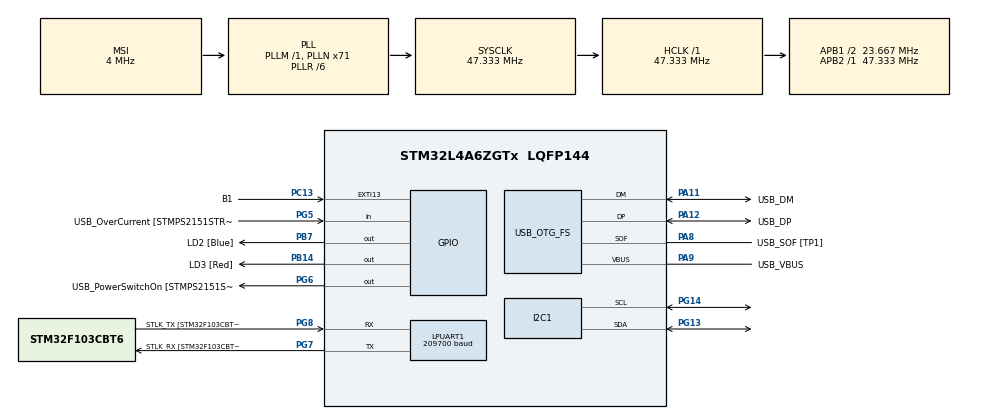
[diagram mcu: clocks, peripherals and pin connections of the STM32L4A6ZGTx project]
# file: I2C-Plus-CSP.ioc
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FREERTOS.Tasks01=defaultTask,24,128,StartDefaultTask,Default,NULL,Dynamic,NULL,NULL;I2C1MasterTask,40,128,vI2CMasterTask,As external,&hi2c1,Dynamic,NULL,NULL
FREERTOS.configUSE_NEWLIB_REENTRANT=1
I2C1.Timing=0x00505B89
LPUART1.AutoBaudRateEnableParam=UART_ADVFEATURE_AUTOBAUDRATE_DISABLE
LPUART1.BaudRate=209700
LPUART1.DMADisableonRxErrorParam=UART_ADVFEATURE_DMA_ENABLEONRXERROR
LPUART1.DataInvertParam=UART_ADVFEATURE_DATAINV_DISABLE
LPUART1.MSBFirstParam=UART_ADVFEATURE_MSBFIRST_DISABLE
LPUART1.Mode=UART_MODE_TX_RX
LPUART1.OneBitSampling=UART_ONE_BIT_SAMPLE_DISABLE
LPUART1.OverrunDisableParam=UART_ADVFEATURE_OVERRUN_ENABLE
LPUART1.Parity=UART_PARITY_NONE
LPUART1.RxPinLevelInvertParam=UART_ADVFEATURE_RXINV_DISABLE
LPUART1.StopBits=UART_STOPBITS_1
LPUART1.SwapParam=UART_ADVFEATURE_SWAP_DISABLE
LPUART1.TxPinLevelInvertParam=UART_ADVFEATURE_TXINV_DISABLE
LPUART1.WordLength=UART_WORDLENGTH_7B
Mcu.Family=STM32L4
Mcu.Name=STM32L4A6ZGTx
Mcu.Package=LQFP144
NVIC.PriorityGroup=NVIC_PRIORITYGROUP_4
NVIC.TIM1_UP_TIM16_IRQn=true\:15\:0\:false\:false\:true\:false\:false\:true\:true
NVIC.TimeBase=TIM1_UP_TIM16_IRQn
NVIC.TimeBaseIP=TIM1
PA10.GPIO_Label=USB_ID
PA10.Signal=USB_OTG_FS_ID
PA11.GPIO_Label=USB_DM
PA11.Mode=Device_Only
PA11.Signal=USB_OTG_FS_DM
PA12.GPIO_Label=USB_DP
PA12.Mode=Device_Only
PA12.Signal=USB_OTG_FS_DP
PA13\ (JTMS/SWDIO).GPIO_Label=TMS
PA13\ (JTMS/SWDIO).Mode=Trace_Asynchronous_SW
PA13\ (JTMS/SWDIO).Signal=SYS_JTMS-SWDIO
PA14\ (JTCK/SWCLK).GPIO_Label=TCK
PA14\ (JTCK/SWCLK).Mode=Trace_Asynchronous_SW
PA14\ (JTCK/SWCLK).Signal=SYS_JTCK-SWCLK
PA8.GPIO_Label=USB_SOF [TP1]
PA8.Mode=Activate_SOF_FS
PA8.Signal=USB_OTG_FS_SOF
PA9.GPIO_Label=USB_VBUS
PA9.Mode=Activate_VBUS
PA9.Signal=USB_OTG_FS_VBUS
PB14.GPIO_Label=LD3 [Red]
PB14.Signal=GPIO_Output
PB3\ (JTDO/TRACESWO).GPIO_Label=SWO
PB3\ (JTDO/TRACESWO).Mode=Trace_Asynchronous_SW
PB3\ (JTDO/TRACESWO).Signal=SYS_JTDO-SWO
PB7.GPIO_Label=LD2 [Blue]
PB7.Signal=GPIO_Output
PC13.GPIO_Label=B1
PC13.Signal=GPXTI13
PC14-OSC32_IN\ (PC14).Mode=LSE-External-Oscillator
PC14-OSC32_IN\ (PC14).Signal=RCC_OSC32_IN
PC15-OSC32_OUT\ (PC15).Mode=LSE-External-Oscillator
PC15-OSC32_OUT\ (PC15).Signal=RCC_OSC32_OUT
PG13.Mode=I2C
PG13.Signal=I2C1_SDA
PG14.Mode=I2C
PG14.Signal=I2C1_SCL
PG5.GPIO_Label=USB_OverCurrent [STMPS2151STR_FAULT]
PG5.Signal=GPIO_Input
PG6.GPIO_Label=USB_PowerSwitchOn [STMPS2151STR_EN]
PG6.Signal=GPIO_Output
PG7.GPIO_Label=STLK_RX [STM32F103CBT6_PA3]
PG7.Mode=Asynchronous
PG7.Signal=LPUART1_TX
PG8.GPIO_Label=STLK_TX [STM32F103CBT6_PA2]
PG8.Mode=Asynchronous
PG8.Signal=LPUART1_RX
PH1-OSC_OUT\ (PH1).Signal=RCC_OSC_OUT
ProjectManager.HeapSize=0x200
ProjectManager.StackSize=0x400
ProjectManager.TargetToolchain=STM32CubeIDE
RCC.ADCFreq_Value=48000000
RCC.AHBFreq_Value=47333333.333333336
RCC.APB1CLKDivider=RCC_HCLK_DIV2
RCC.APB1Freq_Value=23666666.666666668
RCC.APB1TimFreq_Value=47333333.333333336
RCC.APB2Freq_Value=47333333.333333336
RCC.APB2TimFreq_Value=47333333.333333336
RCC.CortexFreq_Value=47333333.333333336
RCC.FLatency=FLASH_LATENCY_2
RCC.HCLKFreq_Value=47333333.333333336
RCC.HSE_VALUE=8000000
RCC.HSI48_VALUE=48000000
RCC.HSI_VALUE=16000000
RCC.MSI_VALUE=4000000
RCC.PLLN=71
RCC.PLLR=RCC_PLLR_DIV6
RCC.PLLSAI1N=24
RCC.SYSCLKFreq_VALUE=47333333.333333336
RCC.SYSCLKSource=RCC_SYSCLKSOURCE_PLLCLK
RCC.USBFreq_Value=48000000
RCC.VCOOutputFreq_Value=284000000
USB_OTG_FS.Sof_enable=ENABLE
USB_OTG_FS.VirtualMode=Device_Only
USB_OTG_FS.battery_charging_enable=ENABLE
USB_OTG_FS.low_power_enable=DISABLE
USB_OTG_FS.lpm_enable=DISABLE
USB_OTG_FS.use_dedicated_ep1=DISABLE
USB_OTG_FS.vbus_sensing_enable=ENABLE
VP_FREERTOS_VS_CMSIS_V2.Mode=CMSIS_V2
VP_SYS_VS_tim1.Mode=TIM1
board=NUCLEO-L4A6ZG

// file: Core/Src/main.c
/* USER CODE BEGIN Header */
/**
  ******************************************************************************
  * @file           : main.c
  * @brief          : Main program body
  ******************************************************************************
  * @attention
  *
  * Copyright (c) 2023 STMicroelectronics.
  * All rights reserved.
  *
  * This software is licensed under terms that can be found in the LICENSE file
  * in the root directory of this software component.
  * If no LICENSE file comes with this software, it is provided AS-IS.
  *
  ******************************************************************************
  */
/* USER CODE END Header */
#include "main.h"
#include "cmsis_os.h"
#include "i2c.h"
#include "usart.h"
#include "usb_otg.h"
#include "gpio.h"

/* USER CODE BEGIN Includes */
#include <stdio.h>
/* USER CODE END Includes */

void SystemClock_Config(void);
void MX_FREERTOS_Init(void);

int main(void)
{

  /* MCU Configuration--------------------------------------------------------*/

  /* Reset of all peripherals, Initializes the Flash interface and the Systick. */
  HAL_Init();

  /* Configure the system clock */
  SystemClock_Config();

  /* Initialize all configured peripherals */
  MX_GPIO_Init();
  MX_LPUART1_UART_Init();
  MX_USB_OTG_FS_PCD_Init();
  MX_I2C1_Init();

  /* Init scheduler */
  osKernelInitialize();  /* Call init function for freertos objects (in freertos.c) */
  MX_FREERTOS_Init();

  /* Start scheduler */
  osKernelStart();

  /* We should never get here as control is now taken by the scheduler */
  /* Infinite loop */
  while (1)
  {

  }
}

void SystemClock_Config(void)
{
  RCC_OscInitTypeDef RCC_OscInitStruct = {0};
  RCC_ClkInitTypeDef RCC_ClkInitStruct = {0};

  /** Configure the main internal regulator output voltage
  */
  if (HAL_PWREx_ControlVoltageScaling(PWR_REGULATOR_VOLTAGE_SCALE1) != HAL_OK)
  {
    Error_Handler();
  }

  /** Configure LSE Drive Capability
  */
  HAL_PWR_EnableBkUpAccess();
  __HAL_RCC_LSEDRIVE_CONFIG(RCC_LSEDRIVE_LOW);

  /** Initializes the RCC Oscillators according to the specified parameters
  * in the RCC_OscInitTypeDef structure.
  */
  RCC_OscInitStruct.OscillatorType = RCC_OSCILLATORTYPE_LSE|RCC_OSCILLATORTYPE_MSI;
  RCC_OscInitStruct.LSEState = RCC_LSE_ON;
  RCC_OscInitStruct.MSIState = RCC_MSI_ON;
  RCC_OscInitStruct.MSICalibrationValue = 0;
  RCC_OscInitStruct.MSIClockRange = RCC_MSIRANGE_6;
  RCC_OscInitStruct.PLL.PLLState = RCC_PLL_ON;
  RCC_OscInitStruct.PLL.PLLSource = RCC_PLLSOURCE_MSI;
  RCC_OscInitStruct.PLL.PLLM = 1;
  RCC_OscInitStruct.PLL.PLLN = 71;
  RCC_OscInitStruct.PLL.PLLP = RCC_PLLP_DIV2;
  RCC_OscInitStruct.PLL.PLLQ = RCC_PLLQ_DIV2;
  RCC_OscInitStruct.PLL.PLLR = RCC_PLLR_DIV6;
  if (HAL_RCC_OscConfig(&RCC_OscInitStruct) != HAL_OK)
  {
    Error_Handler();
  }

  /** Initializes the CPU, AHB and APB buses clocks
  */
  RCC_ClkInitStruct.ClockType = RCC_CLOCKTYPE_HCLK|RCC_CLOCKTYPE_SYSCLK
                              |RCC_CLOCKTYPE_PCLK1|RCC_CLOCKTYPE_PCLK2;
  RCC_ClkInitStruct.SYSCLKSource = RCC_SYSCLKSOURCE_PLLCLK;
  RCC_ClkInitStruct.AHBCLKDivider = RCC_SYSCLK_DIV1;
  RCC_ClkInitStruct.APB1CLKDivider = RCC_HCLK_DIV2;
  RCC_ClkInitStruct.APB2CLKDivider = RCC_HCLK_DIV1;

  if (HAL_RCC_ClockConfig(&RCC_ClkInitStruct, FLASH_LATENCY_2) != HAL_OK)
  {
    Error_Handler();
  }

  /** Enable MSI Auto calibration
  */
  HAL_RCCEx_EnableMSIPLLMode();
}

void HAL_TIM_PeriodElapsedCallback(TIM_HandleTypeDef *htim)
{
  if (htim->Instance == TIM1) {
    HAL_IncTick();
  }
}

void Error_Handler(void)
{
  __disable_irq();
  while (1)
  {
  }
}

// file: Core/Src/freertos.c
/* USER CODE BEGIN Header */
/**
  ******************************************************************************
  * File Name          : freertos.c
  * Description        : Code for freertos applications
  ******************************************************************************
  * @attention
  *
  * Copyright (c) 2023 STMicroelectronics.
  * All rights reserved.
  *
  * This software is licensed under terms that can be found in the LICENSE file
  * in the root directory of this software component.
  * If no LICENSE file comes with this software, it is provided AS-IS.
  *
  ******************************************************************************
  */
/* USER CODE END Header */

#include "FreeRTOS.h"
#include "task.h"
#include "main.h"
#include "cmsis_os.h"

/* USER CODE BEGIN Includes */
#include "i2c.h"
/* USER CODE END Includes */

/* Definitions for defaultTask */
osThreadId_t defaultTaskHandle;
const osThreadAttr_t defaultTask_attributes = {
  .name = "defaultTask",
  .stack_size = 128 * 4,
  .priority = (osPriority_t) osPriorityNormal,
};
/* Definitions for I2C1MasterTask */
osThreadId_t I2C1MasterTaskHandle;
const osThreadAttr_t I2C1MasterTask_attributes = {
  .name = "I2C1MasterTask",
  .stack_size = 128 * 4,
  .priority = (osPriority_t) osPriorityHigh,
};

void StartDefaultTask(void *argument);
extern void vI2CMasterTask(void *argument);

void MX_FREERTOS_Init(void); /* (MISRA C 2004 rule 8.1) */

void MX_FREERTOS_Init(void) {

  /* Create the thread(s) */
  /* creation of defaultTask */
  defaultTaskHandle = osThreadNew(StartDefaultTask, NULL, &defaultTask_attributes);

  /* creation of I2C1MasterTask */
  I2C1MasterTaskHandle = osThreadNew(vI2CMasterTask, (void*) &hi2c1, &I2C1MasterTask_attributes);

}

void StartDefaultTask(void *argument)
{
  /* USER CODE BEGIN StartDefaultTask */
  /* Infinite loop */
  for (;;)
  {
    osDelay(1000);
  }
  /* USER CODE END StartDefaultTask */
}
